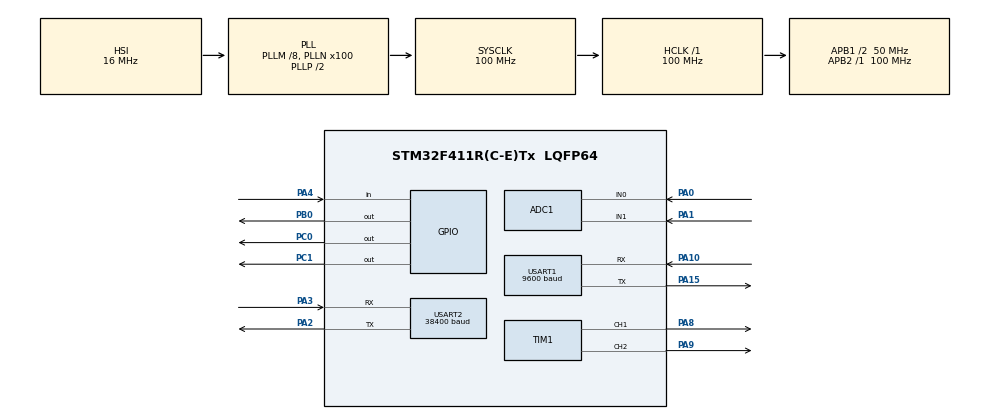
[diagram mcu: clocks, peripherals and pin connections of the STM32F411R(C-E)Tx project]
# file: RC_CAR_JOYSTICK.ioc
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ADC1.Channel-2\#ChannelRegularConversion=ADC_CHANNEL_0
ADC1.NbrOfConversionFlag=1
ADC1.Rank-2\#ChannelRegularConversion=1
ADC1.SamplingTime-2\#ChannelRegularConversion=ADC_SAMPLETIME_3CYCLES
ADC1.master=1
Dma.ADC1.0.Direction=DMA_PERIPH_TO_MEMORY
Dma.ADC1.0.FIFOMode=DMA_FIFOMODE_DISABLE
Dma.ADC1.0.Instance=DMA2_Stream0
Dma.ADC1.0.MemDataAlignment=DMA_MDATAALIGN_HALFWORD
Dma.ADC1.0.MemInc=DMA_MINC_ENABLE
Dma.ADC1.0.Mode=DMA_NORMAL
Dma.ADC1.0.PeriphDataAlignment=DMA_PDATAALIGN_HALFWORD
Dma.ADC1.0.PeriphInc=DMA_PINC_DISABLE
Dma.ADC1.0.Priority=DMA_PRIORITY_LOW
Dma.Request0=ADC1
Mcu.Family=STM32F4
Mcu.Name=STM32F411R(C-E)Tx
Mcu.Package=LQFP64
NVIC.DMA2_Stream0_IRQn=true\:0\:0\:false\:false\:true\:false\:true\:true
NVIC.PriorityGroup=NVIC_PRIORITYGROUP_4
NVIC.USART1_IRQn=true\:0\:0\:false\:false\:true\:true\:true\:true
NVIC.USART2_IRQn=true\:0\:0\:false\:false\:true\:true\:true\:true
PA0-WKUP.Signal=ADCx_IN0
PA1.Signal=ADCx_IN1
PA10.Mode=Asynchronous
PA10.Signal=USART1_RX
PA13.Mode=Serial_Wire
PA13.Signal=SYS_JTMS-SWDIO
PA14.Mode=Serial_Wire
PA14.Signal=SYS_JTCK-SWCLK
PA15.Mode=Asynchronous
PA15.Signal=USART1_TX
PA2.Mode=Asynchronous
PA2.Signal=USART2_TX
PA3.Mode=Asynchronous
PA3.Signal=USART2_RX
PA4.Signal=GPIO_Input
PA8.Signal=S_TIM1_CH1
PA9.Signal=S_TIM1_CH2
PB0.Signal=GPIO_Output
PC0.Signal=GPIO_Output
PC1.Signal=GPIO_Output
PH0\ -\ OSC_IN.Mode=HSE-External-Oscillator
PH0\ -\ OSC_IN.Signal=RCC_OSC_IN
PH1\ -\ OSC_OUT.Mode=HSE-External-Oscillator
PH1\ -\ OSC_OUT.Signal=RCC_OSC_OUT
ProjectManager.HeapSize=0x200
ProjectManager.StackSize=0x400
ProjectManager.TargetToolchain=STM32CubeIDE
RCC.48MHZClocksFreq_Value=50000000
RCC.AHBFreq_Value=100000000
RCC.APB1CLKDivider=RCC_HCLK_DIV2
RCC.APB1Freq_Value=50000000
RCC.APB1TimFreq_Value=100000000
RCC.APB2Freq_Value=100000000
RCC.APB2TimFreq_Value=100000000
RCC.CortexFreq_Value=100000000
RCC.HCLKFreq_Value=100000000
RCC.HSE_VALUE=8000000
RCC.HSI_VALUE=16000000
RCC.LSE_VALUE=32768
RCC.PLLM=8
RCC.PLLN=100
RCC.SYSCLKFreq_VALUE=100000000
RCC.SYSCLKSource=RCC_SYSCLKSOURCE_PLLCLK
RCC.VCOOutputFreq_Value=200000000
SH.ADCx_IN0.0=ADC1_IN0,IN0
SH.ADCx_IN1.0=ADC1_IN1,IN1
SH.S_TIM1_CH1.0=TIM1_CH1,PWM Generation1 CH1
SH.S_TIM1_CH2.0=TIM1_CH2,PWM Generation2 CH2
TIM1.Channel-PWM\ Generation1\ CH1=TIM_CHANNEL_1
TIM1.Channel-PWM\ Generation2\ CH2=TIM_CHANNEL_2
USART1.BaudRate=9600
USART1.VirtualMode=VM_ASYNC
USART2.BaudRate=38400
USART2.VirtualMode=VM_ASYNC
board=custom

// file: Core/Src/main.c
/* USER CODE BEGIN Header */
/**
 ******************************************************************************
 * @file           : main.c
 * @brief          : Main program body
 ******************************************************************************
 * @attention
 *
 * Copyright (c) 2025 STMicroelectronics.
 * All rights reserved.
 *
 * This software is licensed under terms that can be found in the LICENSE file
 * in the root directory of this software component.
 * If no LICENSE file comes with this software, it is provided AS-IS.
 *
 ******************************************************************************
 */
/* USER CODE END Header */
#include "main.h"
#include "adc.h"
#include "dma.h"
#include "tim.h"
#include "usart.h"
#include "gpio.h"

/* USER CODE BEGIN Includes */

#include "moter.h"
#include "stdio.h"
#include "joystick.h"

/* USER CODE END Includes */

void SystemClock_Config(void);

int main(void)
{

  /* MCU Configuration--------------------------------------------------------*/

  /* Reset of all peripherals, Initializes the Flash interface and the Systick. */
  HAL_Init();

  /* Configure the system clock */
  SystemClock_Config();

  /* Initialize all configured peripherals */
  MX_GPIO_Init();
  MX_DMA_Init();
  MX_TIM1_Init();
  MX_USART1_UART_Init();
  MX_ADC1_Init();
  MX_USART2_UART_Init();
  /* USER CODE BEGIN 2 */

	HC05_BindToHC06();		// AT모드 주소 강제 집어넣기

  /* USER CODE END 2 */

  /* Infinite loop */
  /* USER CODE BEGIN WHILE */
	while (1)
	{
		loopJoystick();
		HAL_Delay(50);
    /* USER CODE END WHILE */

	}
}

void SystemClock_Config(void)
{
  RCC_OscInitTypeDef RCC_OscInitStruct = {0};
  RCC_ClkInitTypeDef RCC_ClkInitStruct = {0};

  /** Configure the main internal regulator output voltage
  */
  __HAL_RCC_PWR_CLK_ENABLE();
  __HAL_PWR_VOLTAGESCALING_CONFIG(PWR_REGULATOR_VOLTAGE_SCALE1);

  /** Initializes the RCC Oscillators according to the specified parameters
  * in the RCC_OscInitTypeDef structure.
  */
  RCC_OscInitStruct.OscillatorType = RCC_OSCILLATORTYPE_HSI;
  RCC_OscInitStruct.HSIState = RCC_HSI_ON;
  RCC_OscInitStruct.HSICalibrationValue = RCC_HSICALIBRATION_DEFAULT;
  RCC_OscInitStruct.PLL.PLLState = RCC_PLL_ON;
  RCC_OscInitStruct.PLL.PLLSource = RCC_PLLSOURCE_HSI;
  RCC_OscInitStruct.PLL.PLLM = 8;
  RCC_OscInitStruct.PLL.PLLN = 100;
  RCC_OscInitStruct.PLL.PLLP = RCC_PLLP_DIV2;
  RCC_OscInitStruct.PLL.PLLQ = 4;
  if (HAL_RCC_OscConfig(&RCC_OscInitStruct) != HAL_OK)
  {
    Error_Handler();
  }

  /** Initializes the CPU, AHB and APB buses clocks
  */
  RCC_ClkInitStruct.ClockType = RCC_CLOCKTYPE_HCLK|RCC_CLOCKTYPE_SYSCLK
                              |RCC_CLOCKTYPE_PCLK1|RCC_CLOCKTYPE_PCLK2;
  RCC_ClkInitStruct.SYSCLKSource = RCC_SYSCLKSOURCE_PLLCLK;
  RCC_ClkInitStruct.AHBCLKDivider = RCC_SYSCLK_DIV1;
  RCC_ClkInitStruct.APB1CLKDivider = RCC_HCLK_DIV2;
  RCC_ClkInitStruct.APB2CLKDivider = RCC_HCLK_DIV1;

  if (HAL_RCC_ClockConfig(&RCC_ClkInitStruct, FLASH_LATENCY_3) != HAL_OK)
  {
    Error_Handler();
  }
}

void Error_Handler(void)
{
	__disable_irq();
	while (1)
	{
	}
}
